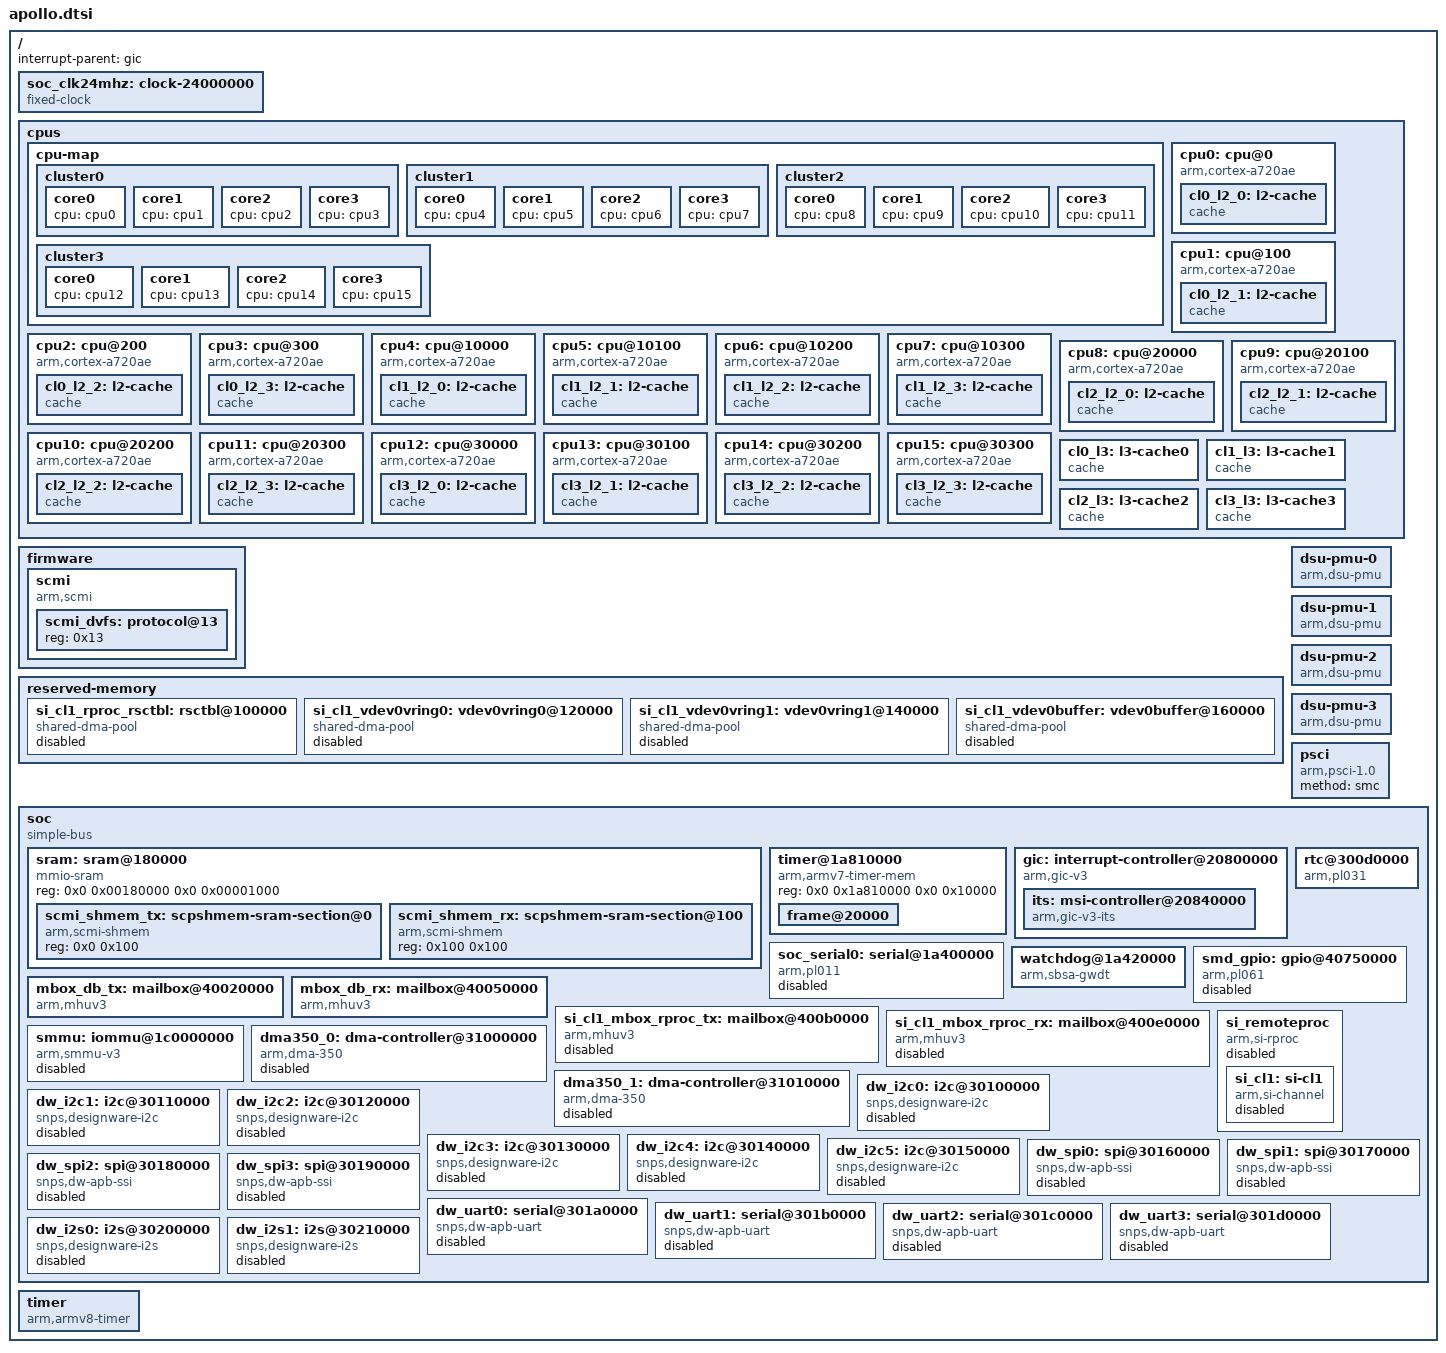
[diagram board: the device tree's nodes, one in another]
// SPDX-License-Identifier: (GPL-2.0 OR BSD-3-Clause)
/*
 * Copyright (c) 2025-2026, Arm Limited. All rights reserved.
 */

#include <dt-bindings/interrupt-controller/arm-gic.h>

/ {
	#address-cells = <2>;
	#size-cells = <2>;
	interrupt-parent = <&gic>;

	soc_clk24mhz: clock-24000000 {
		compatible = "fixed-clock";
		#clock-cells = <0>;
		clock-frequency = <24000000>;
		clock-output-names = "refclk24mhz";
	};

	cpus {
		#address-cells = <2>;
		#size-cells = <0>;

		cpu-map {
			cluster0 {
				core0 { cpu = <&cpu0>; };
				core1 { cpu = <&cpu1>; };
				core2 { cpu = <&cpu2>; };
				core3 { cpu = <&cpu3>; };
			};

			cluster1 {
				core0 { cpu = <&cpu4>; };
				core1 { cpu = <&cpu5>; };
				core2 { cpu = <&cpu6>; };
				core3 { cpu = <&cpu7>; };
			};

			cluster2 {
				core0 { cpu = <&cpu8>; };
				core1 { cpu = <&cpu9>; };
				core2 { cpu = <&cpu10>; };
				core3 { cpu = <&cpu11>; };
			};

			cluster3 {
				core0 { cpu = <&cpu12>; };
				core1 { cpu = <&cpu13>; };
				core2 { cpu = <&cpu14>; };
				core3 { cpu = <&cpu15>; };
			};
		};

		cpu0: cpu@0 {
			compatible = "arm,cortex-a720ae";
			device_type = "cpu";
			reg = <0x00 0x0000>;
			enable-method = "psci";

			clocks = <&scmi_dvfs 0>;
			next-level-cache = <&cl0_l2_0>;

			i-cache-line-size = <64>;
			i-cache-sets = <256>;
			i-cache-size = <0x10000>;

			d-cache-line-size = <64>;
			d-cache-sets = <256>;
			d-cache-size = <0x10000>;

			cl0_l2_0: l2-cache {
				compatible = "cache";
				cache-level = <2>;
				cache-line-size = <64>;
				cache-sets = <0x400>;	/* 8-way set */
				cache-size = <0x80000>;	/* 512KB */
				cache-unified;
				next-level-cache = <&cl0_l3>;
			};
		};

		cpu1: cpu@100 {
			compatible = "arm,cortex-a720ae";
			device_type = "cpu";
			reg = <0x00 0x0100>;
			enable-method = "psci";

			clocks = <&scmi_dvfs 0>;
			next-level-cache = <&cl0_l2_1>;

			i-cache-line-size = <64>;
			i-cache-sets = <256>;
			i-cache-size = <0x10000>;

			d-cache-line-size = <64>;
			d-cache-sets = <256>;
			d-cache-size = <0x10000>;

			cl0_l2_1: l2-cache {
				compatible = "cache";
				cache-level = <2>;
				cache-line-size = <64>;
				cache-sets = <0x400>;	/* 8-way set */
				cache-size = <0x80000>;	/* 512KB */
				cache-unified;
				next-level-cache = <&cl0_l3>;
			};
		};

		cpu2: cpu@200 {
			compatible = "arm,cortex-a720ae";
			device_type = "cpu";
			reg = <0x00 0x0200>;
			enable-method = "psci";

			clocks = <&scmi_dvfs 0>;
			next-level-cache = <&cl0_l2_2>;

			i-cache-line-size = <64>;
			i-cache-sets = <256>;
			i-cache-size = <0x10000>;

			d-cache-line-size = <64>;
			d-cache-sets = <256>;
			d-cache-size = <0x10000>;

			cl0_l2_2: l2-cache {
				compatible = "cache";
				cache-level = <2>;
				cache-line-size = <64>;
				cache-sets = <0x400>;	/* 8-way set */
				cache-size = <0x80000>;	/* 512KB */
				cache-unified;
				next-level-cache = <&cl0_l3>;
			};
		};

		cpu3: cpu@300 {
			compatible = "arm,cortex-a720ae";
			device_type = "cpu";
			reg = <0x00 0x0300>;
			enable-method = "psci";

			clocks = <&scmi_dvfs 0>;
			next-level-cache = <&cl0_l2_3>;

			i-cache-line-size = <64>;
			i-cache-sets = <256>;
			i-cache-size = <0x10000>;

			d-cache-line-size = <64>;
			d-cache-sets = <256>;
			d-cache-size = <0x10000>;

			cl0_l2_3: l2-cache {
				compatible = "cache";
				cache-level = <2>;
				cache-line-size = <64>;
				cache-sets = <0x400>;	/* 8-way set */
				cache-size = <0x80000>;	/* 512KB */
				cache-unified;
				next-level-cache = <&cl0_l3>;
			};
		};

		cpu4: cpu@10000 {
			compatible = "arm,cortex-a720ae";
			device_type = "cpu";
			reg = <0x00 0x10000>;
			enable-method = "psci";

			clocks = <&scmi_dvfs 0>;
			next-level-cache = <&cl1_l2_0>;

			i-cache-line-size = <64>;
			i-cache-sets = <256>;
			i-cache-size = <0x10000>;

			d-cache-line-size = <64>;
			d-cache-sets = <256>;
			d-cache-size = <0x10000>;

			cl1_l2_0: l2-cache {
				compatible = "cache";
				cache-level = <2>;
				cache-line-size = <64>;
				cache-sets = <0x400>;	/* 8-way set */
				cache-size = <0x80000>;	/* 512KB */
				cache-unified;
				next-level-cache = <&cl1_l3>;
			};
		};

		cpu5: cpu@10100 {
			compatible = "arm,cortex-a720ae";
			device_type = "cpu";
			reg = <0x00 0x10100>;
			enable-method = "psci";

			clocks = <&scmi_dvfs 0>;
			next-level-cache = <&cl1_l2_1>;

			i-cache-line-size = <64>;
			i-cache-sets = <256>;
			i-cache-size = <0x10000>;

			d-cache-line-size = <64>;
			d-cache-sets = <256>;
			d-cache-size = <0x10000>;

			cl1_l2_1: l2-cache {
				compatible = "cache";
				cache-level = <2>;
				cache-line-size = <64>;
				cache-sets = <0x400>;	/* 8-way set */
				cache-size = <0x80000>;	/* 512KB */
				cache-unified;
				next-level-cache = <&cl1_l3>;
			};
		};

		cpu6: cpu@10200 {
			compatible = "arm,cortex-a720ae";
			device_type = "cpu";
			reg = <0x00 0x10200>;
			enable-method = "psci";

			clocks = <&scmi_dvfs 0>;
			next-level-cache = <&cl1_l2_2>;

			i-cache-line-size = <64>;
			i-cache-sets = <256>;
			i-cache-size = <0x10000>;

			d-cache-line-size = <64>;
			d-cache-sets = <256>;
			d-cache-size = <0x10000>;

			cl1_l2_2: l2-cache {
				compatible = "cache";
				cache-level = <2>;
				cache-line-size = <64>;
				cache-sets = <0x400>;	/* 8-way set */
				cache-size = <0x80000>;	/* 512KB */
				cache-unified;
				next-level-cache = <&cl1_l3>;
			};
		};

		cpu7: cpu@10300 {
			compatible = "arm,cortex-a720ae";
			device_type = "cpu";
			reg = <0x00 0x10300>;
			enable-method = "psci";

			clocks = <&scmi_dvfs 0>;
			next-level-cache = <&cl1_l2_3>;

			i-cache-line-size = <64>;
			i-cache-sets = <256>;
			i-cache-size = <0x10000>;

			d-cache-line-size = <64>;
			d-cache-sets = <256>;
			d-cache-size = <0x10000>;

			cl1_l2_3: l2-cache {
				compatible = "cache";
				cache-level = <2>;
				cache-line-size = <64>;
				cache-sets = <0x400>;	/* 8-way set */
				cache-size = <0x80000>;	/* 512KB */
				cache-unified;
				next-level-cache = <&cl1_l3>;
			};
		};

		cpu8: cpu@20000 {
			compatible = "arm,cortex-a720ae";
			device_type = "cpu";
			reg = <0x00 0x20000>;
			enable-method = "psci";

			clocks = <&scmi_dvfs 0>;
			next-level-cache = <&cl2_l2_0>;

			i-cache-line-size = <64>;
			i-cache-sets = <256>;
			i-cache-size = <0x10000>;

			d-cache-line-size = <64>;
			d-cache-sets = <256>;
			d-cache-size = <0x10000>;

			cl2_l2_0: l2-cache {
				compatible = "cache";
				cache-level = <2>;
				cache-line-size = <64>;
				cache-sets = <0x400>;	/* 8-way set */
				cache-size = <0x80000>;	/* 512KB */
				cache-unified;
				next-level-cache = <&cl2_l3>;
			};
		};

		cpu9: cpu@20100 {
			compatible = "arm,cortex-a720ae";
			device_type = "cpu";
			reg = <0x00 0x20100>;
			enable-method = "psci";

			clocks = <&scmi_dvfs 0>;
			next-level-cache = <&cl2_l2_1>;

			i-cache-line-size = <64>;
			i-cache-sets = <256>;
			i-cache-size = <0x10000>;

			d-cache-line-size = <64>;
			d-cache-sets = <256>;
			d-cache-size = <0x10000>;

			cl2_l2_1: l2-cache {
				compatible = "cache";
				cache-level = <2>;
				cache-line-size = <64>;
				cache-sets = <0x400>;	/* 8-way set */
				cache-size = <0x80000>;	/* 512KB */
				cache-unified;
				next-level-cache = <&cl2_l3>;
			};
		};

		cpu10: cpu@20200 {
			compatible = "arm,cortex-a720ae";
			device_type = "cpu";
			reg = <0x00 0x20200>;
			enable-method = "psci";

			clocks = <&scmi_dvfs 0>;
			next-level-cache = <&cl2_l2_2>;

			i-cache-line-size = <64>;
			i-cache-sets = <256>;
			i-cache-size = <0x10000>;

			d-cache-line-size = <64>;
			d-cache-sets = <256>;
			d-cache-size = <0x10000>;

			cl2_l2_2: l2-cache {
				compatible = "cache";
				cache-level = <2>;
				cache-line-size = <64>;
				cache-sets = <0x400>;	/* 8-way set */
				cache-size = <0x80000>;	/* 512KB */
				cache-unified;
				next-level-cache = <&cl2_l3>;
			};
		};

		cpu11: cpu@20300 {
			compatible = "arm,cortex-a720ae";
			device_type = "cpu";
			reg = <0x00 0x20300>;
			enable-method = "psci";

			clocks = <&scmi_dvfs 0>;
			next-level-cache = <&cl2_l2_3>;

			i-cache-line-size = <64>;
			i-cache-sets = <256>;
			i-cache-size = <0x10000>;

			d-cache-line-size = <64>;
			d-cache-sets = <256>;
			d-cache-size = <0x10000>;

			cl2_l2_3: l2-cache {
				compatible = "cache";
				cache-level = <2>;
				cache-line-size = <64>;
				cache-sets = <0x400>;	/* 8-way set */
				cache-size = <0x80000>;	/* 512KB */
				cache-unified;
				next-level-cache = <&cl2_l3>;
			};
		};

		cpu12: cpu@30000 {
			compatible = "arm,cortex-a720ae";
			device_type = "cpu";
			reg = <0x00 0x30000>;
			enable-method = "psci";

			clocks = <&scmi_dvfs 0>;
			next-level-cache = <&cl3_l2_0>;

			i-cache-line-size = <64>;
			i-cache-sets = <256>;
			i-cache-size = <0x10000>;

			d-cache-line-size = <64>;
			d-cache-sets = <256>;
			d-cache-size = <0x10000>;

			cl3_l2_0: l2-cache {
				compatible = "cache";
				cache-level = <2>;
				cache-line-size = <64>;
				cache-sets = <0x400>;	/* 8-way set */
				cache-size = <0x80000>;	/* 512KB */
				cache-unified;
				next-level-cache = <&cl3_l3>;
			};
		};

		cpu13: cpu@30100 {
			compatible = "arm,cortex-a720ae";
			device_type = "cpu";
			reg = <0x00 0x30100>;
			enable-method = "psci";

			clocks = <&scmi_dvfs 0>;
			next-level-cache = <&cl3_l2_1>;

			i-cache-line-size = <64>;
			i-cache-sets = <256>;
			i-cache-size = <0x10000>;

			d-cache-line-size = <64>;
			d-cache-sets = <256>;
			d-cache-size = <0x10000>;

			cl3_l2_1: l2-cache {
				compatible = "cache";
				cache-level = <2>;
				cache-line-size = <64>;
				cache-sets = <0x400>;	/* 8-way set */
				cache-size = <0x80000>;	/* 512KB */
				cache-unified;
				next-level-cache = <&cl3_l3>;
			};
		};

		cpu14: cpu@30200 {
			compatible = "arm,cortex-a720ae";
			device_type = "cpu";
			reg = <0x00 0x30200>;
			enable-method = "psci";

			clocks = <&scmi_dvfs 0>;
			next-level-cache = <&cl3_l2_2>;

			i-cache-line-size = <64>;
			i-cache-sets = <256>;
			i-cache-size = <0x10000>;

			d-cache-line-size = <64>;
			d-cache-sets = <256>;
			d-cache-size = <0x10000>;

			cl3_l2_2: l2-cache {
				compatible = "cache";
				cache-level = <2>;
				cache-line-size = <64>;
				cache-sets = <0x400>;	/* 8-way set */
				cache-size = <0x80000>;	/* 512KB */
				cache-unified;
				next-level-cache = <&cl3_l3>;
			};
		};

		cpu15: cpu@30300 {
			compatible = "arm,cortex-a720ae";
			device_type = "cpu";
			reg = <0x00 0x30300>;
			enable-method = "psci";

			clocks = <&scmi_dvfs 0>;
			next-level-cache = <&cl3_l2_3>;

			i-cache-line-size = <64>;
			i-cache-sets = <256>;
			i-cache-size = <0x10000>;

			d-cache-line-size = <64>;
			d-cache-sets = <256>;
			d-cache-size = <0x10000>;

			cl3_l2_3: l2-cache {
				compatible = "cache";
				cache-level = <2>;
				cache-line-size = <64>;
				cache-sets = <0x400>;	/* 8-way set */
				cache-size = <0x80000>;	/* 512KB */
				cache-unified;
				next-level-cache = <&cl3_l3>;
			};
		};

		cl0_l3: l3-cache0 {
			compatible = "cache";
			cache-level = <3>;
			cache-line-size = <64>;
			cache-sets = <0x1000>;		/* 16-way set */
			cache-size = <0x400000>;	/* 4MB */
			cache-unified;
		};

		cl1_l3: l3-cache1 {
			compatible = "cache";
			cache-level = <3>;
			cache-line-size = <64>;
			cache-sets = <0x1000>;		/* 16-way set */
			cache-size = <0x400000>;	/* 4MB */
			cache-unified;
		};

		cl2_l3: l3-cache2 {
			compatible = "cache";
			cache-level = <3>;
			cache-line-size = <64>;
			cache-sets = <0x1000>;		/* 16-way set */
			cache-size = <0x400000>;	/* 4MB */
			cache-unified;
		};

		cl3_l3: l3-cache3 {
			compatible = "cache";
			cache-level = <3>;
			cache-line-size = <64>;
			cache-sets = <0x1000>;		/* 16-way set */
			cache-size = <0x400000>;	/* 4MB */
			cache-unified;
		};
	};

	firmware {
		scmi {
			compatible = "arm,scmi";
			#address-cells = <1>;
			#size-cells = <0>;

			mbox-names = "tx", "tx_reply", "rx";
			mboxes = <&mbox_db_tx 0 0 0>,
				 <&mbox_db_rx 0 0 0>,
				 <&mbox_db_rx 0 0 2>;
			shmem = <&scmi_shmem_tx &scmi_shmem_rx>;

			scmi_dvfs: protocol@13 {
				reg = <0x13>;
				#clock-cells = <1>;
			};
		};
	};

	reserved-memory {
		#address-cells = <2>;
		#size-cells = <2>;
		ranges;

		si_cl1_rproc_rsctbl: rsctbl@100000 {
			status = "disabled";
			compatible = "shared-dma-pool";
			reg = <0x0 0x00100000 0x0 0x20000>;
			no-map;
		};

		si_cl1_vdev0vring0: vdev0vring0@120000 {
			status = "disabled";
			compatible = "shared-dma-pool";
			reg = <0x0 0x00120000 0x0 0x20000>;
			no-map;
		};

		si_cl1_vdev0vring1: vdev0vring1@140000 {
			status = "disabled";
			compatible = "shared-dma-pool";
			reg = <0x0 0x00140000 0x0 0x20000>;
			no-map;
		};

		si_cl1_vdev0buffer: vdev0buffer@160000 {
			status = "disabled";
			compatible = "shared-dma-pool";
			reg = <0x0 0x00160000 0x0 0x20000>;
			no-map;
		};
	};

	dsu-pmu-0 {
		compatible = "arm,dsu-pmu";
		cpus = <&cpu0 &cpu1 &cpu2 &cpu3>;
		interrupts = <GIC_SPI 216 IRQ_TYPE_EDGE_RISING>;
	};

	dsu-pmu-1 {
		compatible = "arm,dsu-pmu";
		cpus = <&cpu4 &cpu5 &cpu6 &cpu7>;
		interrupts = <GIC_SPI 217 IRQ_TYPE_EDGE_RISING>;
	};

	dsu-pmu-2 {
		compatible = "arm,dsu-pmu";
		cpus = <&cpu8 &cpu9 &cpu10 &cpu11>;
		interrupts = <GIC_SPI 218 IRQ_TYPE_EDGE_RISING>;
	};

	dsu-pmu-3 {
		compatible = "arm,dsu-pmu";
		cpus = <&cpu12 &cpu13 &cpu14 &cpu15>;
		interrupts = <GIC_SPI 219 IRQ_TYPE_EDGE_RISING>;
	};

	psci {
		compatible = "arm,psci-1.0", "arm,psci-0.2";
		method = "smc";
	};

	soc: soc {
		compatible = "simple-bus";
		#address-cells = <2>;
		#size-cells = <2>;
		ranges;

		sram: sram@180000 {
			compatible = "mmio-sram";
			reg = <0x0 0x00180000 0x0 0x00001000>;
			#address-cells = <1>;
			#size-cells = <1>;
			ranges = <0 0x0 0x00180000 0x00001000>;

			scmi_shmem_tx: scpshmem-sram-section@0 {
				compatible = "arm,scmi-shmem";
				reg = <0x0 0x100>;
			};

			scmi_shmem_rx: scpshmem-sram-section@100 {
				compatible = "arm,scmi-shmem";
				reg = <0x100 0x100>;
			};
		};

		timer@1a810000 {
			compatible = "arm,armv7-timer-mem";
			reg = <0x0 0x1a810000 0x0 0x10000>;
			#address-cells = <1>;
			#size-cells = <1>;

			/*
			 * Map child space [0x0..0x30000) to parent @ 0x1a810000
			 */
			ranges = <0x0 0x0 0x1a810000 0x00030000>;

			frame@20000 {
				reg = <0x20000 0x10000>;
				frame-number = <0>;
				interrupts = <GIC_SPI 49 IRQ_TYPE_LEVEL_HIGH>;
			};
		};

		gic: interrupt-controller@20800000 {
			compatible = "arm,gic-v3";
			#interrupt-cells = <3>;
			#address-cells = <2>;
			#size-cells = <2>;
			#redistributor-regions = <16>;
			interrupt-controller;
			interrupts = <GIC_PPI 9 IRQ_TYPE_LEVEL_HIGH>;
			ranges;

			/*
			 * With GIC-A720AE multiview enabled, GICR_TYPER.Last is
			 * always reported as 1 on redistributor views other than
			 * view 0. This breaks discovery of a single contiguous
			 * GICR frame region, so each core is described with its own
			 * redistributor region.
			 */
			reg = <0x0 0x20800000 0x0 0x10000>,	/* GICD */
			      <0x0 0x20880000 0x0 0x40000>,	/* 16 * GICR */
			      <0x0 0x208c0000 0x0 0x40000>,
			      <0x0 0x20900000 0x0 0x40000>,
			      <0x0 0x20940000 0x0 0x40000>,
			      <0x0 0x20980000 0x0 0x40000>,
			      <0x0 0x209c0000 0x0 0x40000>,
			      <0x0 0x20a00000 0x0 0x40000>,
			      <0x0 0x20a40000 0x0 0x40000>,
			      <0x0 0x20a80000 0x0 0x40000>,
			      <0x0 0x20ac0000 0x0 0x40000>,
			      <0x0 0x20b00000 0x0 0x40000>,
			      <0x0 0x20b40000 0x0 0x40000>,
			      <0x0 0x20b80000 0x0 0x40000>,
			      <0x0 0x20bc0000 0x0 0x40000>,
			      <0x0 0x20c00000 0x0 0x40000>,
			      <0x0 0x20c40000 0x0 0x40000>;

			its: msi-controller@20840000 {
				compatible = "arm,gic-v3-its";
				reg = <0x0 0x20840000 0x0 0x40000>;
				msi-controller;
				#msi-cells = <1>;
			};
		};

		/*
		 * UART is fixed at 24MHz, both UARTCLK and PCLK.
		 */
		soc_serial0: serial@1a400000 {
			compatible = "arm,pl011", "arm,primecell";
			reg = <0x0 0x1a400000 0x0 0x10000>;
			interrupts = <GIC_SPI 52 IRQ_TYPE_LEVEL_HIGH>;
			clocks = <&soc_clk24mhz>, <&soc_clk24mhz>;
			clock-names = "uartclk", "apb_pclk";
			status = "disabled";
		};

		watchdog@1a420000 {
			compatible = "arm,sbsa-gwdt";
			reg = <0x0 0x1a420000 0x0 0x10000>,
			      <0x0 0x1a430000 0x0 0x10000>;
			interrupts = <GIC_SPI 50 IRQ_TYPE_LEVEL_HIGH>;
		};

		rtc@300d0000 {
			compatible = "arm,pl031", "arm,primecell";
			reg = <0x0 0x300d0000 0x0 0x10000>;
			interrupts = <GIC_SPI 268 IRQ_TYPE_LEVEL_HIGH>;
			clocks = <&soc_clk24mhz>;
			clock-names = "apb_pclk";
		};

		smd_gpio: gpio@40750000 {
			compatible = "arm,pl061", "arm,primecell";
			reg = <0x0 0x40750000 0x0 0x1000>;
			interrupts = <GIC_SPI 193 IRQ_TYPE_LEVEL_HIGH>;
			clocks = <&soc_clk24mhz>;
			clock-names = "apb_pclk";
			gpio-controller;
			#gpio-cells = <2>;
			interrupt-controller;
			#interrupt-cells = <2>;
			status = "disabled";
		};

		mbox_db_tx: mailbox@40020000 {
			compatible = "arm,mhuv3";
			reg = <0x0 0x40020000 0x0 0x30000>;
			interrupts = <GIC_SPI 112 IRQ_TYPE_LEVEL_HIGH>;
			interrupt-names = "pbx-dbch-xfer-ack-0";
			clocks = <&soc_clk24mhz>;
			#mbox-cells = <3>;
		};

		mbox_db_rx: mailbox@40050000 {
			compatible = "arm,mhuv3";
			reg = <0x0 0x40050000 0x0 0x30000>;
			interrupts = <GIC_SPI 113 IRQ_TYPE_LEVEL_HIGH>;
			interrupt-names = "combined";
			clocks = <&soc_clk24mhz>;
			#mbox-cells = <3>;
		};

		si_cl1_mbox_rproc_tx: mailbox@400b0000 {
			status = "disabled";
			compatible = "arm,mhuv3";
			reg = <0x0 0x400b0000 0x0 0x30000>;
			interrupts = <GIC_SPI 120 IRQ_TYPE_LEVEL_HIGH>;
			interrupt-names = "combined";
			clocks = <&soc_clk24mhz>;
			#mbox-cells = <3>;
		};

		si_cl1_mbox_rproc_rx: mailbox@400e0000 {
			status = "disabled";
			compatible = "arm,mhuv3";
			reg = <0x0 0x400e0000 0x0 0x30000>;
			interrupts = <GIC_SPI 121 IRQ_TYPE_LEVEL_HIGH>;
			interrupt-names = "combined";
			clocks = <&soc_clk24mhz>;
			#mbox-cells = <3>;
		};

		si_remoteproc: si_remoteproc {
			status = "disabled";
			compatible = "arm,si-rproc";
			#address-cells = <2>;
			#size-cells = <2>;
			ranges;

			si_cl1: si-cl1 {
				status = "disabled";
				compatible = "arm,si-channel";
				#address-cells = <1>;
				#size-cells = <1>;
				ranges = <0x0 0x0 0x0 0x100000>;
				memory-region = <&si_cl1_rproc_rsctbl>,
						<&si_cl1_vdev0vring0>,
						<&si_cl1_vdev0vring1>,
						<&si_cl1_vdev0buffer>;
				mboxes = <&si_cl1_mbox_rproc_rx 0 0 0>,
					 <&si_cl1_mbox_rproc_rx 0 0 1>,
					 <&si_cl1_mbox_rproc_tx 0 0 0>,
					 <&si_cl1_mbox_rproc_tx 0 0 1>,
					 <&si_cl1_mbox_rproc_tx 0 0 2>,
					 <&si_cl1_mbox_rproc_tx 0 0 3>,
					 <&si_cl1_mbox_rproc_rx 0 0 2>;
				mbox-names = "vq0_rx", "vq1_rx", "vq0_tx",
					     "vq1_tx", "detach", "attach",
					     "ack";
			};
		};
	};

	timer {
		compatible = "arm,armv8-timer";
		interrupts = <GIC_PPI 13 IRQ_TYPE_LEVEL_LOW>,
			     <GIC_PPI 14 IRQ_TYPE_LEVEL_LOW>,
			     <GIC_PPI 11 IRQ_TYPE_LEVEL_LOW>,
			     <GIC_PPI 10 IRQ_TYPE_LEVEL_LOW>,
			     <GIC_PPI 12 IRQ_TYPE_LEVEL_LOW>;
	};
};

&soc {
	smmu: iommu@1c0000000 {
		compatible = "arm,smmu-v3";
		reg = <0x1 0xc0000000 0x0 0x8000000>;
		dma-coherent;
		#iommu-cells = <1>;
		interrupts = <GIC_SPI 65 IRQ_TYPE_EDGE_RISING>;
		interrupt-names = "combined";
		msi-parent = <&its 0x10000>;
		status = "disabled";
	};

	dma350_0: dma-controller@31000000 {
		compatible = "arm,dma-350";
		reg = <0x0 0x31000000 0x0 0x10000>;
		interrupts = <GIC_SPI 279 IRQ_TYPE_LEVEL_HIGH>,
			     <GIC_SPI 279 IRQ_TYPE_LEVEL_HIGH>,
			     <GIC_SPI 279 IRQ_TYPE_LEVEL_HIGH>,
			     <GIC_SPI 279 IRQ_TYPE_LEVEL_HIGH>,
			     <GIC_SPI 279 IRQ_TYPE_LEVEL_HIGH>,
			     <GIC_SPI 279 IRQ_TYPE_LEVEL_HIGH>,
			     <GIC_SPI 279 IRQ_TYPE_LEVEL_HIGH>,
			     <GIC_SPI 279 IRQ_TYPE_LEVEL_HIGH>;
		#dma-cells = <1>;
		status = "disabled";
	};

	dma350_1: dma-controller@31010000 {
		compatible = "arm,dma-350";
		reg = <0x0 0x31010000 0x0 0x10000>;
		interrupts = <GIC_SPI 358 IRQ_TYPE_LEVEL_HIGH>,
			     <GIC_SPI 358 IRQ_TYPE_LEVEL_HIGH>,
			     <GIC_SPI 358 IRQ_TYPE_LEVEL_HIGH>,
			     <GIC_SPI 358 IRQ_TYPE_LEVEL_HIGH>,
			     <GIC_SPI 358 IRQ_TYPE_LEVEL_HIGH>,
			     <GIC_SPI 358 IRQ_TYPE_LEVEL_HIGH>,
			     <GIC_SPI 358 IRQ_TYPE_LEVEL_HIGH>,
			     <GIC_SPI 358 IRQ_TYPE_LEVEL_HIGH>;
		#dma-cells = <1>;
		status = "disabled";
	};

	dw_i2c0: i2c@30100000 {
		compatible = "snps,designware-i2c";
		reg = <0x0 0x30100000 0x0 0x10000>;
		interrupts = <GIC_SPI 320 IRQ_TYPE_LEVEL_HIGH>;
		clocks = <&soc_clk24mhz>, <&soc_clk24mhz>;
		clock-names = "ref", "pclk";
		#address-cells = <1>;
		#size-cells = <0>;

		status = "disabled";
	};

	dw_i2c1: i2c@30110000 {
		compatible = "snps,designware-i2c";
		reg = <0x0 0x30110000 0x0 0x10000>;
		interrupts = <GIC_SPI 321 IRQ_TYPE_LEVEL_HIGH>;
		clocks = <&soc_clk24mhz>, <&soc_clk24mhz>;
		clock-names = "ref", "pclk";
		#address-cells = <1>;
		#size-cells = <0>;

		status = "disabled";
	};

	dw_i2c2: i2c@30120000 {
		compatible = "snps,designware-i2c";
		reg = <0x0 0x30120000 0x0 0x10000>;
		interrupts = <GIC_SPI 322 IRQ_TYPE_LEVEL_HIGH>;
		clocks = <&soc_clk24mhz>, <&soc_clk24mhz>;
		clock-names = "ref", "pclk";
		#address-cells = <1>;
		#size-cells = <0>;

		status = "disabled";
	};

	dw_i2c3: i2c@30130000 {
		compatible = "snps,designware-i2c";
		reg = <0x0 0x30130000 0x0 0x10000>;
		interrupts = <GIC_SPI 323 IRQ_TYPE_LEVEL_HIGH>;
		clocks = <&soc_clk24mhz>, <&soc_clk24mhz>;
		clock-names = "ref", "pclk";
		#address-cells = <1>;
		#size-cells = <0>;

		status = "disabled";
	};

	dw_i2c4: i2c@30140000 {
		compatible = "snps,designware-i2c";
		reg = <0x0 0x30140000 0x0 0x10000>;
		interrupts = <GIC_SPI 324 IRQ_TYPE_LEVEL_HIGH>;
		clocks = <&soc_clk24mhz>, <&soc_clk24mhz>;
		clock-names = "ref", "pclk";
		#address-cells = <1>;
		#size-cells = <0>;

		status = "disabled";
	};

	dw_i2c5: i2c@30150000 {
		compatible = "snps,designware-i2c";
		reg = <0x0 0x30150000 0x0 0x10000>;
		interrupts = <GIC_SPI 325 IRQ_TYPE_LEVEL_HIGH>;
		clocks = <&soc_clk24mhz>, <&soc_clk24mhz>;
		clock-names = "ref", "pclk";
		#address-cells = <1>;
		#size-cells = <0>;

		status = "disabled";
	};

	dw_spi0: spi@30160000 {
		compatible = "snps,dw-apb-ssi";
		reg = <0x0 0x30160000 0x0 0x10000>;
		interrupts = <GIC_SPI 326 IRQ_TYPE_LEVEL_HIGH>;
		clocks = <&soc_clk24mhz>, <&soc_clk24mhz>;
		clock-names = "ssi_clk", "pclk";
		reg-io-width = <4>;
		#address-cells = <1>;
		#size-cells = <0>;
		dmas = <&dma350_0 0>, <&dma350_0 1>;
		dma-names = "tx", "rx";

		status = "disabled";
	};

	dw_spi1: spi@30170000 {
		compatible = "snps,dw-apb-ssi";
		reg = <0x0 0x30170000 0x0 0x10000>;
		interrupts = <GIC_SPI 327 IRQ_TYPE_LEVEL_HIGH>;
		clocks = <&soc_clk24mhz>, <&soc_clk24mhz>;
		clock-names = "ssi_clk", "pclk";
		reg-io-width = <4>;
		#address-cells = <1>;
		#size-cells = <0>;
		dmas = <&dma350_0 2>, <&dma350_0 3>;
		dma-names = "tx", "rx";

		status = "disabled";
	};

	dw_spi2: spi@30180000 {
		compatible = "snps,dw-apb-ssi";
		reg = <0x0 0x30180000 0x0 0x10000>;
		interrupts = <GIC_SPI 328 IRQ_TYPE_LEVEL_HIGH>;
		clocks = <&soc_clk24mhz>, <&soc_clk24mhz>;
		clock-names = "ssi_clk", "pclk";
		reg-io-width = <4>;
		#address-cells = <1>;
		#size-cells = <0>;

		status = "disabled";
	};

	dw_spi3: spi@30190000 {
		compatible = "snps,dw-apb-ssi";
		reg = <0x0 0x30190000 0x0 0x10000>;
		interrupts = <GIC_SPI 329 IRQ_TYPE_LEVEL_HIGH>;
		clocks = <&soc_clk24mhz>, <&soc_clk24mhz>;
		clock-names = "ssi_clk", "pclk";
		reg-io-width = <4>;
		#address-cells = <1>;
		#size-cells = <0>;

		status = "disabled";
	};

	dw_uart0: serial@301a0000 {
		compatible = "snps,dw-apb-uart";
		reg = <0x0 0x301a0000 0x0 0x10000>;
		interrupts = <GIC_SPI 330 IRQ_TYPE_LEVEL_HIGH>;
		clocks = <&soc_clk24mhz>, <&soc_clk24mhz>;
		clock-names = "baudclk", "apb_pclk";
		reg-shift = <2>;
		reg-io-width = <4>;
		dmas = <&dma350_0 4>, <&dma350_0 5>;
		dma-names = "tx", "rx";
		status = "disabled";
	};

	dw_uart1: serial@301b0000 {
		compatible = "snps,dw-apb-uart";
		reg = <0x0 0x301b0000 0x0 0x10000>;
		interrupts = <GIC_SPI 331 IRQ_TYPE_LEVEL_HIGH>;
		clocks = <&soc_clk24mhz>, <&soc_clk24mhz>;
		clock-names = "baudclk", "apb_pclk";
		reg-shift = <2>;
		reg-io-width = <4>;
		dmas = <&dma350_0 6>, <&dma350_0 7>;
		dma-names = "tx", "rx";
		status = "disabled";
	};

	dw_uart2: serial@301c0000 {
		compatible = "snps,dw-apb-uart";
		reg = <0x0 0x301c0000 0x0 0x10000>;
		interrupts = <GIC_SPI 332 IRQ_TYPE_LEVEL_HIGH>;
		clocks = <&soc_clk24mhz>, <&soc_clk24mhz>;
		clock-names = "baudclk", "apb_pclk";
		reg-shift = <2>;
		reg-io-width = <4>;
		status = "disabled";
	};

	dw_uart3: serial@301d0000 {
		compatible = "snps,dw-apb-uart";
		reg = <0x0 0x301d0000 0x0 0x10000>;
		interrupts = <GIC_SPI 333 IRQ_TYPE_LEVEL_HIGH>;
		clocks = <&soc_clk24mhz>, <&soc_clk24mhz>;
		clock-names = "baudclk", "apb_pclk";
		reg-shift = <2>;
		reg-io-width = <4>;
		status = "disabled";
	};

	dw_i2s0: i2s@30200000 {
		compatible = "snps,designware-i2s";
		reg = <0x0 0x30200000 0x0 0x10000>;
		interrupts = <GIC_SPI 356 IRQ_TYPE_LEVEL_HIGH>;
		#sound-dai-cells = <0>;
		dmas = <&dma350_1 0>, <&dma350_1 1>;
		dma-names = "tx", "rx";
		status = "disabled";
	};

	dw_i2s1: i2s@30210000 {
		compatible = "snps,designware-i2s";
		reg = <0x0 0x30210000 0x0 0x10000>;
		interrupts = <GIC_SPI 357 IRQ_TYPE_LEVEL_HIGH>;
		#sound-dai-cells = <0>;
		dmas = <&dma350_1 2>, <&dma350_1 3>;
		dma-names = "tx", "rx";
		status = "disabled";
	};
};

#include "apollo-pinctrl.dtsi"
